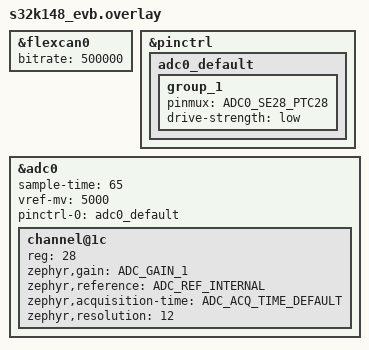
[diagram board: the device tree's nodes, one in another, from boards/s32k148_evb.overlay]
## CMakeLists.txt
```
cmake_minimum_required(VERSION 3.20.0)

set(OPENBSW_DIR
    ${CMAKE_CURRENT_SOURCE_DIR}/../../../openbsw
    CACHE PATH "Path to Eclipse OpenBSW")

set(INCLUDE_OPENBSW_LIBS_BSP
    OFF
    CACHE BOOL "Include openbsw/libs/bsp/ in build")

# make sure zephyr compiler options are also set for cmake modules not depending on zephyr
add_compile_options($<TARGET_PROPERTY:zephyr_interface,INTERFACE_COMPILE_OPTIONS>)

find_package(Zephyr REQUIRED HINTS $ENV{ZEPHYR_BASE})

project(demo_app)

if (CONFIG_NETWORKING)
        add_compile_definitions(PLATFORM_SUPPORT_ETHERNET=1)
endif()

if (CONFIG_CAN)
        add_compile_definitions(PLATFORM_SUPPORT_CAN=1)
        add_compile_definitions(PLATFORM_SUPPORT_UDS=1)
endif()

include(${OPENBSW_DIR}/Filelists.cmake)

target_include_directories(app
        PRIVATE
        include)

target_sources(app 
        PRIVATE 
        src/console/console.cpp
        src/systems/DemoSystem.cpp
        src/systems/RuntimeSystem.cpp
        src/systems/SysAdminSystem.cpp
        src/uds/DiagSession.cpp
        src/uds/ReadIdentifierPot.cpp
        src/logger/logger.cpp
        src/main.cpp)

if (CONFIG_TRACING_USER)
target_sources(app PRIVATE src/TraceHooks.cpp)
endif()

if (CONFIG_CAN)
target_sources(app
        PRIVATE
        src/systems/CanSystem.cpp
        src/systems/DoCanSystem.cpp
        src/systems/TransportSystem.cpp
        src/systems/UdsSystem.cpp)
endif()

# Path to libraries for adaptation of OpenBSW to Zephyr
add_subdirectory(${CMAKE_CURRENT_SOURCE_DIR}/../../libs openbsw_zephyr_libs)

add_subdirectory(openbswConfig)

add_library(asyncPlatform ALIAS asyncZephyr)

target_link_libraries(app PUBLIC
        asyncBinding
        asyncConsole
        asyncZephyrImpl
        configuration
        common
        cpp2can
        canTransceiverZephyr
        docan
        lifecycle
        lifecycleSupport
        logger
        loggerIntegration
        stdioConsoleInput
        transport
        transportRouterSimple
        uds
        etl
        bspZephyr)

if (CONFIG_NETWORKING)
target_link_libraries(app PUBLIC
        zephyrEthAdapter)
endif()
```

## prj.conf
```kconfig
CONFIG_CPP=y
CONFIG_STD_CPP14=y
CONFIG_REQUIRES_FULL_LIBCPP=y
CONFIG_EVENTS=y
CONFIG_THREAD_NAME=y

# needed for stack size measurement
CONFIG_THREAD_STACK_INFO=y
CONFIG_INIT_STACKS=y

# task switch tracing
CONFIG_TRACING=y
CONFIG_TRACING_USER=y

CONFIG_SERIAL=y

CONFIG_CAN=y
CONFIG_CAN_INIT_PRIORITY=80
CONFIG_CAN_MAX_FILTER=1

CONFIG_PWM=y

CONFIG_ADC=y
CONFIG_ADC_MCUX_ADC12=y

CONFIG_NO_OPTIMIZATIONS=n
CONFIG_REBOOT=y

# small timeout in case a cable is not connected
CONFIG_NET_CONFIG_INIT_TIMEOUT=1

CONFIG_NET_LOG=y
```

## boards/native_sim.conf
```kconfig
CONFIG_PWM=n
CONFIG_CAN_NATIVE_LINUX=y
CONFIG_UART_NATIVE_POSIX=y
CONFIG_NATIVE_UART_0_ON_OWN_PTY=y

CONFIG_NETWORKING=y
CONFIG_NET_IPV4=y
CONFIG_NET_ARP=y
CONFIG_NET_UDP=y
CONFIG_NET_TCP=y
CONFIG_NET_SOCKETS=y

CONFIG_NET_CONFIG_SETTINGS=y
CONFIG_NET_CONFIG_NEED_IPV4=y
CONFIG_NET_CONFIG_MY_IPV4_ADDR="192.0.2.1"
CONFIG_NET_CONFIG_PEER_IPV4_ADDR="192.0.2.2"

CONFIG_NATIVE_SIM_REBOOT=y
```

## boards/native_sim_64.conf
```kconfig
CONFIG_PWM=n
CONFIG_CAN_NATIVE_LINUX=y
CONFIG_UART_NATIVE_POSIX=y
CONFIG_NATIVE_UART_0_ON_OWN_PTY=y
CONFIG_ADC=n
CONFIG_ADC_MCUX_ADC12=n
```

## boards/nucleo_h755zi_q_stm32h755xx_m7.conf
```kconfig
CONFIG_NETWORKING=y
CONFIG_NET_IPV4=y
CONFIG_NET_ARP=y
CONFIG_NET_UDP=y
CONFIG_NET_TCP=y
CONFIG_NET_SOCKETS=y
CONFIG_POSIX_API=y

CONFIG_NET_DHCPV4=n

CONFIG_NET_MAX_CONTEXTS=10
CONFIG_NET_PKT_TX_COUNT=20
CONFIG_NET_BUF_TX_COUNT=50

CONFIG_NET_BUF_LOG=n
CONFIG_NET_LOG=n

CONFIG_NET_CONFIG_SETTINGS=y
CONFIG_NET_CONFIG_MY_IPV4_ADDR="192.0.2.1"
CONFIG_NET_CONFIG_PEER_IPV4_ADDR="192.0.2.2"

#CONFIG_NET_SHELL=y
```

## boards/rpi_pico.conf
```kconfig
CONFIG_CAN=n
```

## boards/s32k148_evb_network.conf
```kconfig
CONFIG_NETWORKING=y
CONFIG_POSIX_API=y
CONFIG_NET_UDP=y
CONFIG_NET_TCP=y
CONFIG_NET_ARP=y

CONFIG_TEST_RANDOM_GENERATOR=y

# Network application options and configuration
CONFIG_NET_CONFIG_SETTINGS=y
CONFIG_NET_CONFIG_NEED_IPV4=y
CONFIG_NET_CONFIG_MY_IPV4_ADDR="192.0.2.1"
CONFIG_NET_CONFIG_PEER_IPV4_ADDR="192.0.2.2"
```

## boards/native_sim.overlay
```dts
/ {
    chosen {
        zephyr,canbus = &can0;
    };
};

&can0 {
    host-interface = "vcan0";
    bus-speed = <500000>;
    status = "okay";
};
```

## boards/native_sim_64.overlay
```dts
/ {
    chosen {
        zephyr,canbus = &can0;
    };
};

&can0 {
    host-interface = "vcan0";
    bus-speed = <500000>;
    status = "okay";
};
```

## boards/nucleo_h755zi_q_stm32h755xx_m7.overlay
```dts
&fdcan1 {
    bus-speed = <500000>;
};

/ {
    chosen {
        zephyr,canbus = &fdcan1;
    };
};

&fdcan1 {
	pinctrl-0 = <&fdcan1_rx_pb8 &fdcan1_tx_pb9>;
	pinctrl-names = "default";
	clocks = <&rcc STM32_CLOCK_BUS_APB1_2 0x00000100>,
		 <&rcc STM32_SRC_PLL2_Q FDCAN_SEL(2)>;
	status = "okay";
};
```

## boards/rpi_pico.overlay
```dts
&pwm_led0 {
    status = "okay";
};

&pwm {
    status = "okay";
    divider-frac-4 = <15>;
    divider-int-4 = <255>;
};
```

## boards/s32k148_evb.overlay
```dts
#include <zephyr/dt-bindings/adc/adc.h>

&flexcan0 {
    bitrate = <500000>;
};

&pinctrl {
    adc0_default: adc0_default {
        group_1 {
            pinmux = <ADC0_SE28_PTC28>;
            drive-strength = "low";
        };
    };
};

&adc0 {
    #address-cells = <1>;
    #size-cells = <0>;

    channel@1c {
        reg = <28>;
        zephyr,gain = "ADC_GAIN_1";
        zephyr,reference = "ADC_REF_INTERNAL";
        zephyr,acquisition-time = <ADC_ACQ_TIME_DEFAULT>;
        zephyr,resolution = <12>;
    };

    sample-time = <65>;
    vref-mv = <5000>;
    pinctrl-0 = <&adc0_default>;
    pinctrl-names = "default";
    status = "okay";
};
```

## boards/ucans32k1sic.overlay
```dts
&flexcan0 {
    bus-speed = <500000>;
};
```

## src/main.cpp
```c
// Copyright 2024 Accenture.

#include <stdio.h>
#include <zephyr/kernel.h>
#include <zephyr/arch/cpu.h>
#include <zephyr/sys/printk.h>
#include <zephyr/sys/reboot.h>
#include <async/AsyncBinding.h>
#include <logger/logger.h>
#include <console/console.h>
#include "app/DemoLogger.h"
#include "app/appConfig.h"
#include <lifecycle/LifecycleLogger.h>
#include <lifecycle/LifecycleManager.h>
#include "systems/DemoSystem.h"
#include "systems/RuntimeSystem.h"
#include "systems/SysAdminSystem.h"

#ifdef PLATFORM_SUPPORT_CAN
#include "systems/CanSystem.h"
#include "systems/TransportSystem.h"
#include "systems/UdsSystem.h"
#include "systems/DoCanSystem.h"
#endif

using ::util::logger::LIFECYCLE;
using ::util::logger::DEMO;
using ::util::logger::Logger;

using AsyncAdapter        = ::async::AsyncBinding::AdapterType;
using AsyncRuntimeMonitor = ::async::AsyncBinding::RuntimeMonitorType;
using AsyncContextHook    = ::async::AsyncBinding::ContextHookType;

constexpr size_t MaxNumComponents         = 16;
constexpr size_t MaxNumLevels             = 8;
constexpr size_t MaxNumComponentsPerLevel = MaxNumComponents;

using LifecycleManager = ::lifecycle::declare::
    LifecycleManager<MaxNumComponents, MaxNumLevels, MaxNumComponentsPerLevel>;

char const* const isrGroupNames[ISR_GROUP_COUNT] = {
    "test",
    "can"
#ifdef PLATFORM_SUPPORT_ETHERNET
    , "ethernet"
#endif
};

AsyncRuntimeMonitor runtimeMonitor{
    AsyncContextHook::InstanceType::GetNameType::create<&AsyncAdapter::getTaskName>(),
    isrGroupNames};

LifecycleManager lifecycleManager{
    TASK_SYSADMIN,
    ::lifecycle::LifecycleManager::GetTimestampType::create<&getSystemTimeUs32Bit>()};

::systems::RuntimeSystem runtimeSystem{TASK_BACKGROUND, runtimeMonitor};
::systems::SysAdminSystem sysAdminSystem{TASK_SYSADMIN, lifecycleManager};

#ifdef PLATFORM_SUPPORT_CAN
::systems::CanSystem canSystem{TASK_CAN};
::transport::TransportSystem transportSystem{TASK_UDS};
::docan::DoCanSystem doCanSystem{transportSystem, canSystem, TASK_CAN};
::uds::UdsSystem udsSystem{lifecycleManager, transportSystem, TASK_UDS, LOGICAL_ADDRESS};
#endif

::systems::DemoSystem demoSystem{
    TASK_DEMO,
    lifecycleManager
#ifdef PLATFORM_SUPPORT_CAN
    ,
    canSystem
#endif
};

K_THREAD_STACK_DEFINE(sysadminStack, 1024);
using SysadminTask = AsyncAdapter::Task<TASK_SYSADMIN, K_THREAD_STACK_SIZEOF(sysadminStack)>;
SysadminTask sysadminTask{"sysadmin", sysadminStack};

K_THREAD_STACK_DEFINE(demoStack, 4 * 1024);
using DemoTask = AsyncAdapter::Task<TASK_DEMO, K_THREAD_STACK_SIZEOF(demoStack)>;
DemoTask demoTask{"demo", demoStack};

K_THREAD_STACK_DEFINE(canStack, 1024);
using CanTask = AsyncAdapter::Task<TASK_CAN, K_THREAD_STACK_SIZEOF(canStack)>;
CanTask canTask{"can", canStack};

K_THREAD_STACK_DEFINE(udsStack, 2 * 1024);
using UdsTask = AsyncAdapter::Task<TASK_UDS, K_THREAD_STACK_SIZEOF(udsStack)>;
UdsTask udsTask{"uds", udsStack};

K_THREAD_STACK_DEFINE(backgroundStack, 1024);
using BackgroundTask = AsyncAdapter::Task<TASK_BACKGROUND, K_THREAD_STACK_SIZEOF(backgroundStack)>;
BackgroundTask backgroundTask{"background", backgroundStack};

AsyncContextHook contextHook{runtimeMonitor};

::async::TimeoutType timeout;
::async::TimeoutType timeout2;

class LifecycleMonitor : private ::lifecycle::ILifecycleListener
{
public:
    explicit LifecycleMonitor(LifecycleManager& manager) { manager.addLifecycleListener(*this); }

    bool isReadyForReset() const { return _isReadyForReset; }

private:
    void lifecycleLevelReached(
        uint8_t const level,
        ::lifecycle::ILifecycleComponent::Transition::Type const /* transition */) override
    {
        if (0 == level)
        {
            _isReadyForReset = true;
        }
    }

private:
    bool _isReadyForReset = false;
};

void staticShutdown()
{
    Logger::info(LIFECYCLE, "Lifecycle shutdown complete");
    ::logger::flush();

    sys_reboot(SYS_REBOOT_COLD);
}

LifecycleMonitor lifecycleMonitor(lifecycleManager);

class DemoRunnable : public ::async::IRunnable
{
public:
    explicit DemoRunnable() {};

    void execute() override {
        Logger::debug(DEMO, "demo ctx: %d name: %s", 
            AsyncAdapter::getCurrentTaskContext(),
            AsyncAdapter::getTaskName(AsyncAdapter::getCurrentTaskContext()));
        if (AsyncAdapter::getCurrentTaskContext() == TASK_SYSADMIN) {
            async::execute(TASK_DEMO, *this);
        }
    };
};

class DemoRunnable2 : public ::async::IRunnable
{
public:
    explicit DemoRunnable2() {};

    void execute() override {
        ::logger::run();
        ::console::run();
    };
};

DemoRunnable demoRunnable;
DemoRunnable2 demoRunnable2;

int main(void)
{
    ::logger::init();

    ::console::init();
    ::console::enable();

    AsyncAdapter::init();

    lifecycleManager.addComponent("runtime", runtimeSystem, 1U);
#ifdef PLATFORM_SUPPORT_CAN
    lifecycleManager.addComponent("can", canSystem, 2U);
    lifecycleManager.addComponent("transport", transportSystem, 4U);
    lifecycleManager.addComponent("docan", doCanSystem, 5U);
    lifecycleManager.addComponent("uds", udsSystem, 6U);
#endif
    lifecycleManager.addComponent("sysadmin", sysAdminSystem, 7U);
    lifecycleManager.addComponent("demo", demoSystem, 8U);

    lifecycleManager.transitionToLevel(MaxNumLevels);

    runtimeMonitor.start();

    AsyncAdapter::run();

    ::async::scheduleAtFixedRate(
        TASK_SYSADMIN, demoRunnable, timeout, 1000, ::async::TimeUnit::MILLISECONDS);
    ::async::scheduleAtFixedRate(
        TASK_DEMO, demoRunnable2, timeout2, 10, ::async::TimeUnit::MILLISECONDS);

    while (1) {
        k_msleep(1000);
        if (lifecycleMonitor.isReadyForReset())
        {
            staticShutdown();
        }
    }

    return 0;
}
```

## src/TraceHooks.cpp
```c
// Copyright 2024 Accenture.

#include "async/Config.h"
#include "async/Hook.h"

#include <tracing_user.h>
#include <zephyr/init.h>

#if defined(CONFIG_SOC_SERIES_S32K1)
#define FLEXCAN_NODE DT_NODELABEL(flexcan0)
#ifdef PLATFORM_SUPPORT_ETHERNET
#define ENET_MAC_NODE DT_NODELABEL(enet_mac)
#endif

static int32_t const canIrqNums[DT_IRQN(FLEXCAN_NODE)]
    = {DT_IRQ_BY_IDX(FLEXCAN_NODE, 0, irq),
       DT_IRQ_BY_IDX(FLEXCAN_NODE, 1, irq),
       DT_IRQ_BY_IDX(FLEXCAN_NODE, 2, irq),
       DT_IRQ_BY_IDX(FLEXCAN_NODE, 3, irq),
       DT_IRQ_BY_IDX(FLEXCAN_NODE, 4, irq)};

#ifdef PLATFORM_SUPPORT_ETHERNET
static int32_t const enetMacIrqNums[DT_IRQN(ENET_MAC_NODE)]
    = {DT_IRQ_BY_IDX(ENET_MAC_NODE, 0, irq),
       DT_IRQ_BY_IDX(ENET_MAC_NODE, 1, irq),
       DT_IRQ_BY_IDX(ENET_MAC_NODE, 2, irq)};
#endif

#endif

/**
 * Tracing works via weak symbols.
 * To put the trace hook implementations here is a workaround to make sure
 * the weak symbols defined in the zephyr lib get overwritten.
 * Symbols in the zephyrAdapterImpl lib can not overwrite the weak symbols
 * since the zephyr lib is first in link order (because of the dependency).
 * This could be solved by putting the zephyrAdapterImpl in between the
 * --whole-archive section of the linking.
 */
extern "C"
{
static bool _application_initialized = false;

void sys_trace_thread_switched_in_user(void)
{
    /**
     * Ignore hook if application hasn't been initialized, i.e. constructors haven't been called yet.
     * Otherwise handling of the async hooks could cause problems.
     */
    if (!_application_initialized)
    {
        return;
    }

    unsigned int key = irq_lock();

    /* Can't use k_current_get as thread base and z_tls_current might be incorrect */
    int prio = k_thread_priority_get(k_sched_current_thread_query());
    asyncEnterTask(prio - 1);

    irq_unlock(key);
}

void sys_trace_thread_switched_out_user(void)
{
    /**
     * Ignore hook if application hasn't been initialized, i.e. constructors haven't been called yet.
     * Otherwise handling of the async hooks could cause problems.
     */
    if (!_application_initialized)
    {
        return;
    }

    unsigned int key = irq_lock();

    /* Can't use k_current_get as thread base and z_tls_current might be incorrect */
    int prio = k_thread_priority_get(k_sched_current_thread_query());
    asyncLeaveTask(prio - 1);

    irq_unlock(key);
}

void sys_trace_isr_enter_user(void)
{
    /**
     * Ignore hook if application hasn't been initialized, i.e. constructors haven't been called yet.
     * Otherwise handling of the async hooks could cause problems.
     */
    if (!_application_initialized)
    {
        return;
    }
#ifdef CONFIG_ARM

#if defined(CONFIG_ARM_CUSTOM_INTERRUPT_CONTROLLER)
    int32_t irqNo = z_soc_irq_get_active();
#else
    int32_t irqNo = __get_IPSR();
#endif
    irqNo -= 16;

#endif

#if defined(CONFIG_SOC_SERIES_S32K1)
    for (uint8_t i = 0; i < sizeof(canIrqNums) / sizeof(int32_t); i++)
    {
        if (irqNo == canIrqNums[i])
        {
            asyncEnterIsrGroup(ISR_GROUP_CAN);
            return;
        }
    }
#ifdef PLATFORM_SUPPORT_ETHERNET
    for (uint8_t i = 0; i < sizeof(enetMacIrqNums) / sizeof(int32_t); i++)
    {
        if (irqNo == enetMacIrqNums[i])
        {
            asyncEnterIsrGroup(ISR_GROUP_ETHERNET);
            return;
        }
    }
#endif
    asyncEnterIsrGroup(ISR_GROUP_TEST);
#else
    asyncEnterIsrGroup(ISR_GROUP_TEST);
#endif
}

void sys_trace_isr_exit_user(void)
{
    /**
     * Ignore hook if application hasn't been initialized, i.e. constructors haven't been called yet.
     * Otherwise handling of the async hooks could cause problems.
     */
    if (!_application_initialized)
    {
        return;
    }
#ifdef CONFIG_ARM

#if defined(CONFIG_ARM_CUSTOM_INTERRUPT_CONTROLLER)
    int32_t irqNo = z_soc_irq_get_active();
#else
    int32_t irqNo = __get_IPSR();
#endif
    irqNo -= 16;

#endif

#if defined(CONFIG_SOC_SERIES_S32K1)
    for (uint8_t i = 0; i < sizeof(canIrqNums) / sizeof(int32_t); i++)
    {
        if (irqNo == canIrqNums[i])
        {
            asyncLeaveIsrGroup(ISR_GROUP_CAN);
            return;
        }
    }
#ifdef PLATFORM_SUPPORT_ETHERNET
    for (uint8_t i = 0; i < sizeof(enetMacIrqNums) / sizeof(int32_t); i++)
    {
        if (irqNo == enetMacIrqNums[i])
        {
            asyncLeaveIsrGroup(ISR_GROUP_ETHERNET);
            return;
        }
    }
#endif
    asyncLeaveIsrGroup(ISR_GROUP_TEST);
#else
    asyncLeaveIsrGroup(ISR_GROUP_TEST);
#endif
}

static int application_initialized(void)
{
    _application_initialized = true;
    return 0;
}

/** 
 * We use the switch to the APPLICATION level to know that constructors have been invoked.
 */
SYS_INIT(application_initialized, APPLICATION, CONFIG_KERNEL_INIT_PRIORITY_DEFAULT);

}
```
